VERSION ""

NS_ :

BS_:

BU_: DBG VCU BMS MCM

BO_ 162 MCM_Temperatures3: 8 MCM
 SG_ MCM_Motor_Temperature : 32|16@1+ (1,0) [-100|1000] "C" VCU

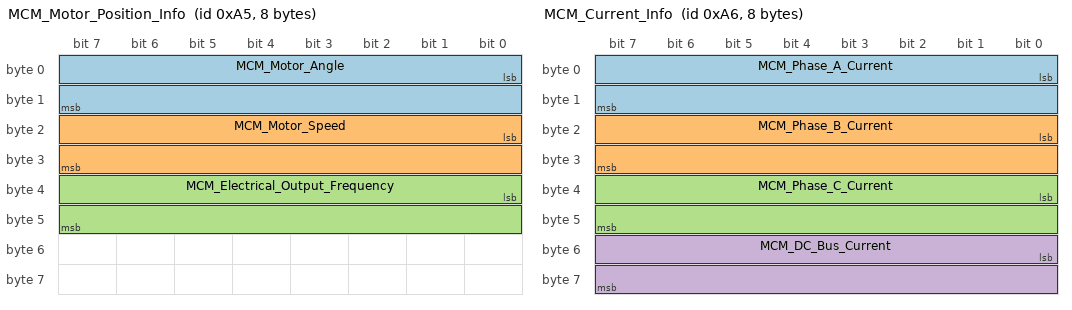
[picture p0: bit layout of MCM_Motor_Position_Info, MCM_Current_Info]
BO_ 165 MCM_Motor_Position_Info: 8 MCM
 SG_ MCM_Motor_Angle : 0|16@1+ (1,0) [-360|360] "DEG" VCU
 SG_ MCM_Motor_Speed : 16|16@1+ (1,0) [-7000|7000] "RPM" VCU
 SG_ MCM_Electrical_Output_Frequency : 32|16@1+ (1,0) [0|120] "Hz" VCU
 SG_ MCM_Resolver Angle : 48|16@1+ (1,0) [-360|360] "DEG" VCU

BO_ 166 MCM_Current_Info: 8 MCM
 SG_ MCM_Phase_A_Current : 0|16@1+ (1,0) [-400|400] "A" VCU
 SG_ MCM_Phase_B_Current : 16|16@1+ (1,0) [-400|400] "A" VCU
 SG_ MCM_Phase_C_Current : 32|16@1+ (1,0) [-400|400] "A" VCU
 SG_ MCM_DC_Bus_Current : 48|16@1+ (1,0) [-400|400] "A" VCU

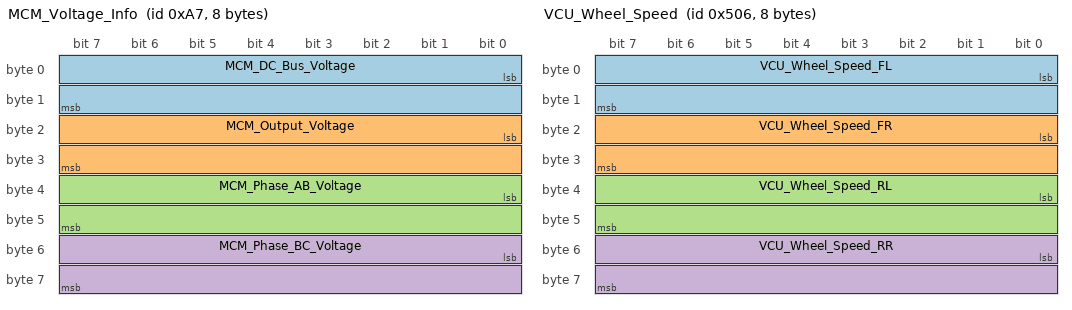
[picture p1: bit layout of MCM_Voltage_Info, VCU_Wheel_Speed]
BO_ 167 MCM_Voltage_Info: 8 MCM
 SG_ MCM_DC_Bus_Voltage : 0|16@1+ (1,0) [-470|470] "V" VCU
 SG_ MCM_Output_Voltage : 16|16@1+ (1,0) [-470|470] "V" VCU
 SG_ MCM_Phase_AB_Voltage : 32|16@1+ (1,0) [-470|470] "V" VCU
 SG_ MCM_Phase_BC_Voltage : 48|16@1+ (1,0) [-470|470] "V" VCU

BO_ 1280 VCU_TPS0: 8 VCU
 SG_ VCU_TPS0_Value : 16|16@1- (0.0946969697,-714) [0|100] "%" VCU

BO_ 1281 VCU_TPS1: 8 VCU
 SG_ VCU_TPS1_Value : 16|16@1- (0.0916590284,-3563) [0|100] "%" VCU

BO_ 1282 VCU_BPS: 8 VCU
 SG_ VCU_BPS_Value : 16|16@1- (0.02,0) [0|100] "%" VCU

BO_ 1283 VCU_WSS: 8 VCU
 SG_ VCU_WSS_Value : 0|64@1+ (1,0) [0|0] "" VCU

BO_ 1284 VCU_WSS1: 8 VCU
 SG_ VCU_WSS1_Value : 0|64@1+ (1,0) [0|0] "" VCU

BO_ 1285 VCU_WSS2: 8 VCU
 SG_ VCU_WSS2_Value : 0|64@1+ (1,0) [0|0] "" VCU

BO_ 1286 VCU_Wheel_Speed: 8 VCU
 SG_ VCU_Wheel_Speed_FL : 0|16@1+ (1,0) [0|100000] "mm/s" VCU
 SG_ VCU_Wheel_Speed_FR : 16|16@1+ (1,0) [0|100000] "mm/s" VCU
 SG_ VCU_Wheel_Speed_RL : 32|16@1+ (1,0) [0|100000] "mm/s" VCU
 SG_ VCU_Wheel_Speed_RR : 48|16@1+ (1,0) [0|100000] "mm/s" VCU

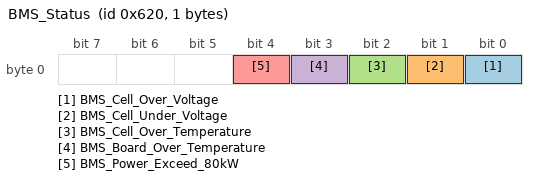
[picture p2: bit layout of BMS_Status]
BO_ 1568 BMS_Status: 1 BMS
 SG_ BMS_Cell_Over_Voltage : 0|1@1+ (1,0) [0|0] "" VCU
 SG_ BMS_Cell_Under_Voltage : 1|1@1+ (1,0) [0|0] "" VCU
 SG_ BMS_Cell_Over_Temperature : 2|1@1+ (1,0) [0|0] "" VCU
 SG_ BMS_Board_Over_Temperature : 3|1@1+ (1,0) [0|0] "" VCU
 SG_ BMS_Power_Exceed_80kW : 4|1@1+ (1,0) [0|0] "" VCU

BO_ 1571 BMS_Pack_Info: 8 BMS
 SG_ BMS_Pack_Voltage : 0|32@1- (0.01,0) [0|300] "V" VCU
 SG_ BMS_Pack_Current : 32|32@1- (0.01,-3000) [-3000|3000] "A" VCU

BO_ 1572 BMS_Load_Info: 8 BMS
 SG_ BMS_Load_Voltage : 0|32@1- (0.01,0) [0|300] "V" VCU
 SG_ BMS_Load_Current : 32|32@1- (0.01,-3000) [-3000|3000] "A" VCU

BO_ 1573 BMS_Cell_Voltage_High_Low: 8 BMS
 SG_ BMS_Cell_Voltage_High : 0|32@1- (0.01,0) [0|6.55] "V" VCU
 SG_ BMS_Cell_Voltage_Low : 32|32@1- (0.01,0) [0|6.55] "V" VCU

BO_ 1574 BMS_Cell_Voltage_Average: 8 BMS
 SG_ BMS_Cell_Voltage_Average : 0|32@1- (0.01,0) [0|6.55] "V" VCU
 SG_ BMS_Cell_Voltage_Mismatch : 32|32@1- (0.01,0) [0|6.55] "V" VCU

BO_ 1575 BMS_Status_Soc: 8 BMS
 SG_ BMS_SOC : 0|32@1- (0.1,0) [0|100] "%" VCU
 SG_ BMS_Capacity : 32|32@1- (0.1,0) [0|30] "Ah" VCU

BO_ 1576 BMS_Temperature_Average: 8 BMS
 SG_ BMS_Cell_Temperature_Average : 0|32@1- (0.1,-100) [-100|100] "C" VCU
 SG_ BMS_Board_Temperature_Average : 32|32@1- (0.1,-100) [-100|100] "C" VCU

BO_ 1577 BMS_Cell_Temperature: 8 BMS
 SG_ BMS_Cell_Temperature_High : 0|32@1- (0.1,-100) [-100|100] "C" VCU
 SG_ BMS_Cell_Temperature_Low : 32|32@1- (0.1,-100) [-100|100] "C" VCU

BO_ 1584 BMS_Board_Temperature: 8 BMS
 SG_ BMS_Board_Temperature_High : 0|32@1- (0.1,-100) [-100|100] "C" VCU
 SG_ BMS_Board_Temperature_Low : 32|32@1- (0.1,-100) [-100|100] "C" VCU

BO_ 1585 BMS_Load_Power: 4 BMS
 SG_ BMS_Load_Power : 0|32@1- (0.1,-100000) [-100000|100000] "W" VCU

CM_ BU_ VCU "The vehicle control unit";
CM_ BU_ MCM "The motor controller of the car";
CM_ BU_ BMS "The battery management system";
CM_ BO_ 162 "Motor Controller Temperatures #3";
CM_ BO_ 165 "Motor Position Information";
CM_ BO_ 166 "Motor Current Information";
CM_ BO_ 167 "Motor Voltage Information";
CM_ BO_ 1280 "Throttle Position Sensor 0 Value";
CM_ BO_ 1281 "Throttle Position Sensor 1 Value";
CM_ BO_ 1282 "Brake Pressure Sensor Value";
CM_ BO_ 1283 "Wheel Speed Sensor Value";
CM_ BO_ 1284 "Wheel Speed Sensor 1 Value";
CM_ BO_ 1285 "Wheel Speed Sensor 2 Value";
CM_ BO_ 1286 "Wheel Speeds (mm/s)";
CM_ BO_ 1568 "BMS Status and Fault Message";
CM_ BO_ 1571 "Accumulator Pack Voltage and Current";
CM_ BO_ 1572 "Accumulator Load Voltage and Current";
CM_ BO_ 1573 "Cell Voltage High and Low";
CM_ BO_ 1574 "Cell Voltage Average and Mismatch";
CM_ BO_ 1575 "SOC Percentage and Battery Capacity";
CM_ BO_ 1576 "Cell and BMS Board Temperature Average";
CM_ BO_ 1577 "Cell Temperature High and Low";
CM_ BO_ 1584 "Accumulator Load Power";

BA_DEF_ "BusType" STRING ;
BA_DEF_ SG_ "FieldType" STRING ;

BA_DEF_DEF_ "BusType" "CAN";
BA_DEF_DEF_ "FieldType" "";

BA_ "FieldType" SG_ 100 DRIVER_HEARTBEAT_cmd "DRIVER_HEARTBEAT_cmd";

VAL_ 100 DRIVER_HEARTBEAT_cmd 2 "DRIVER_HEARTBEAT_cmd_REBOOT" 1 "DRIVER_HEARTBEAT_cmd_SYNC" 0 "DRIVER_HEARTBEAT_cmd_NOOP" ;
